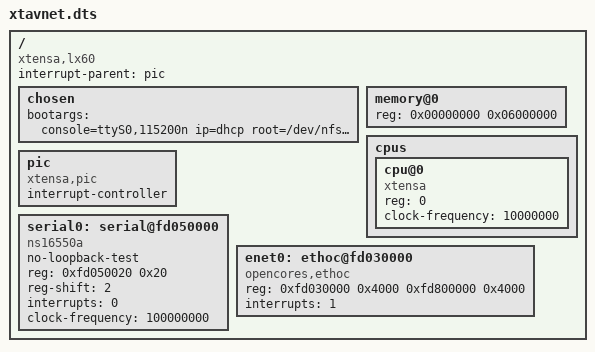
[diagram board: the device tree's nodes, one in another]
/dts-v1/;
/ {
	compatible = "xtensa,lx60";
	#address-cells = <1>;
	#size-cells = <1>;
	interrupt-parent = <&pic>;

	chosen {
		bootargs = "console=ttyS0,115200n ip=dhcp root=/dev/nfs rw debug";
	};

	memory@0 {
		device_type = "memory";
		reg = <0x00000000 0x06000000>;
	};

	cpus {
		#address-cells = <1>;
		#size-cells = <0>;
		cpu@0 {
			compatible = "xtensa";
			reg = <0>;
			clock-frequency = <10000000>;
		};
	};

	pic: pic {
		compatible = "xtensa,pic";
		#interrupt-cells = <1>;
		interrupt-controller;
	};

	serial0: serial@fd050000 {
		compatible = "ns16550a";
		no-loopback-test;
		reg = <0xfd050020 0x20>;
		reg-shift = <2>;
		interrupts = <0>;
		clock-frequency = <100000000>;
	};

	enet0: ethoc@fd030000 {
		compatible = "opencores,ethoc";
		reg = <0xfd030000 0x4000 0xfd800000 0x4000>;
		interrupts = <1>;
	};
};
